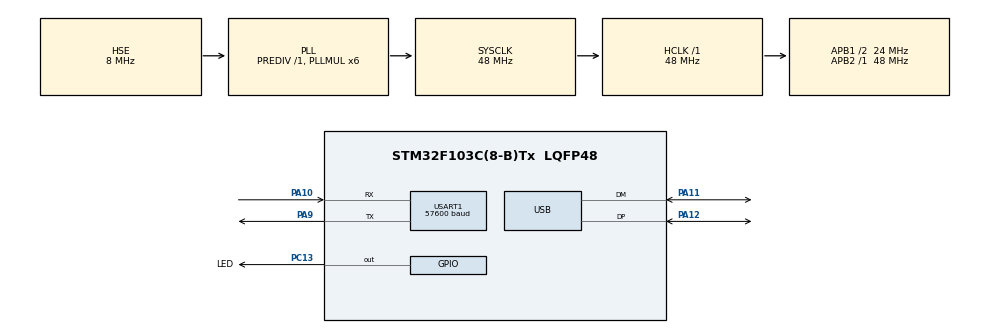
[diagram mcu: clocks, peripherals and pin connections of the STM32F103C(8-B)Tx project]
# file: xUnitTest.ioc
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Mcu.Family=STM32F1
Mcu.Name=STM32F103C(8-B)Tx
Mcu.Package=LQFP48
NVIC.PriorityGroup=NVIC_PRIORITYGROUP_4
NVIC.TIM1_UP_IRQn=true\:0\:0\:false\:false\:true
NVIC.TimeBase=TIM1_UP_IRQn
NVIC.TimeBaseIP=TIM1
PA10.Mode=Asynchronous
PA10.Signal=USART1_RX
PA11.Mode=Device
PA11.Signal=USB_DM
PA12.Mode=Device
PA12.Signal=USB_DP
PA13.Mode=JTAG_5_pins
PA13.Signal=SYS_JTMS-SWDIO
PA14.Mode=JTAG_5_pins
PA14.Signal=SYS_JTCK-SWCLK
PA15.Mode=JTAG_5_pins
PA15.Signal=SYS_JTDI
PA9.Mode=Asynchronous
PA9.Signal=USART1_TX
PB3.Mode=JTAG_5_pins
PB3.Signal=SYS_JTDO-TRACESWO
PB4.Mode=JTAG_5_pins
PB4.Signal=SYS_NJTRST
PC13-TAMPER-RTC.GPIO_Label=LED
PC13-TAMPER-RTC.GPIO_ModeDefaultOutputPP=GPIO_MODE_OUTPUT_PP
PC13-TAMPER-RTC.GPIO_Speed=GPIO_SPEED_FREQ_HIGH
PC13-TAMPER-RTC.Signal=GPIO_Output
PC14-OSC32_IN.Mode=LSE-External-Oscillator
PC14-OSC32_IN.Signal=RCC_OSC32_IN
PC15-OSC32_OUT.Mode=LSE-External-Oscillator
PC15-OSC32_OUT.Signal=RCC_OSC32_OUT
PD0-OSC_IN.Mode=HSE-External-Oscillator
PD0-OSC_IN.Signal=RCC_OSC_IN
PD1-OSC_OUT.Mode=HSE-External-Oscillator
PD1-OSC_OUT.Signal=RCC_OSC_OUT
ProjectManager.HeapSize=0x200
ProjectManager.StackSize=0x400
ProjectManager.TargetToolchain=SW4STM32
RCC.AHBFreq_Value=48000000
RCC.APB1CLKDivider=RCC_HCLK_DIV2
RCC.APB1Freq_Value=24000000
RCC.APB1TimFreq_Value=48000000
RCC.APB2Freq_Value=48000000
RCC.APB2TimFreq_Value=48000000
RCC.HCLKFreq_Value=48000000
RCC.HSIState=RCC_HSI_ON
RCC.PLLMUL=RCC_PLL_MUL6
RCC.SYSCLKFreq_VALUE=48000000
RCC.SYSCLKSource=RCC_SYSCLKSOURCE_PLLCLK
RCC.USBFreq_Value=48000000
USART1.BaudRate=57600
VP_SYS_VS_tim1.Mode=TIM1
board=UartTest

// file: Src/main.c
/**
  ******************************************************************************
  * File Name          : main.c
  * Description        : Main program body
  ******************************************************************************
  *
  * COPYRIGHT(c) 2017 STMicroelectronics
  *
  * Redistribution and use in source and binary forms, with or without modification,
  * are permitted provided that the following conditions are met:
  *   1. Redistributions of source code must retain the above copyright notice,
  *      this list of conditions and the following disclaimer.
  *   2. Redistributions in binary form must reproduce the above copyright notice,
  *      this list of conditions and the following disclaimer in the documentation
  *      and/or other materials provided with the distribution.
  *   3. Neither the name of STMicroelectronics nor the names of its contributors
  *      may be used to endorse or promote products derived from this software
  *      without specific prior written permission.
  *
  * THIS SOFTWARE IS PROVIDED BY THE COPYRIGHT HOLDERS AND CONTRIBUTORS "AS IS"
  * AND ANY EXPRESS OR IMPLIED WARRANTIES, INCLUDING, BUT NOT LIMITED TO, THE
  * IMPLIED WARRANTIES OF MERCHANTABILITY AND FITNESS FOR A PARTICULAR PURPOSE ARE
  * DISCLAIMED. IN NO EVENT SHALL THE COPYRIGHT HOLDER OR CONTRIBUTORS BE LIABLE
  * FOR ANY DIRECT, INDIRECT, INCIDENTAL, SPECIAL, EXEMPLARY, OR CONSEQUENTIAL
  * DAMAGES (INCLUDING, BUT NOT LIMITED TO, PROCUREMENT OF SUBSTITUTE GOODS OR
  * SERVICES; LOSS OF USE, DATA, OR PROFITS; OR BUSINESS INTERRUPTION) HOWEVER
  * CAUSED AND ON ANY THEORY OF LIABILITY, WHETHER IN CONTRACT, STRICT LIABILITY,
  * OR TORT (INCLUDING NEGLIGENCE OR OTHERWISE) ARISING IN ANY WAY OUT OF THE USE
  * OF THIS SOFTWARE, EVEN IF ADVISED OF THE POSSIBILITY OF SUCH DAMAGE.
  *
  ******************************************************************************
  */
#include "main.h"
#include "stm32f1xx_hal.h"

UART_HandleTypeDef huart1;

PCD_HandleTypeDef hpcd_USB_FS;

/* USER CODE BEGIN PV */
/* Private variables ---------------------------------------------------------*/

/* USER CODE END PV */

void SystemClock_Config(void);
void Error_Handler(void);
static void MX_GPIO_Init(void);
static void MX_USART1_UART_Init(void);
static void MX_USB_PCD_Init(void);

/* USER CODE BEGIN PFP */
/* Private function prototypes -----------------------------------------------*/

/* USER CODE END PFP */

int main(void)
{

  /* MCU Configuration----------------------------------------------------------*/

  /* Reset of all peripherals, Initializes the Flash interface and the Systick. */
  HAL_Init();

  /* Configure the system clock */
  SystemClock_Config();

  /* Initialize all configured peripherals */
  MX_GPIO_Init();
  MX_USART1_UART_Init();
  MX_USB_PCD_Init();

  /* Infinite loop */
  while (1)
  {

  /* USER CODE BEGIN 3 */
	HAL_GPIO_TogglePin(LED_GPIO_Port, LED_Pin); //Toggle the state of pin PC13
	HAL_Delay(500);
  }
  /* USER CODE END 3 */

}

/** System Clock Configuration
*/
void SystemClock_Config(void)
{

  RCC_OscInitTypeDef RCC_OscInitStruct;
  RCC_ClkInitTypeDef RCC_ClkInitStruct;
  RCC_PeriphCLKInitTypeDef PeriphClkInit;

    /**Initializes the CPU, AHB and APB busses clocks
    */
  RCC_OscInitStruct.OscillatorType = RCC_OSCILLATORTYPE_HSE;
  RCC_OscInitStruct.HSEState = RCC_HSE_ON;
  RCC_OscInitStruct.HSEPredivValue = RCC_HSE_PREDIV_DIV1;
  RCC_OscInitStruct.HSIState = RCC_HSI_ON;
  RCC_OscInitStruct.PLL.PLLState = RCC_PLL_ON;
  RCC_OscInitStruct.PLL.PLLSource = RCC_PLLSOURCE_HSE;
  RCC_OscInitStruct.PLL.PLLMUL = RCC_PLL_MUL6;
  if (HAL_RCC_OscConfig(&RCC_OscInitStruct) != HAL_OK)
  {
    Error_Handler();
  }

    /**Initializes the CPU, AHB and APB busses clocks
    */
  RCC_ClkInitStruct.ClockType = RCC_CLOCKTYPE_HCLK|RCC_CLOCKTYPE_SYSCLK
                              |RCC_CLOCKTYPE_PCLK1|RCC_CLOCKTYPE_PCLK2;
  RCC_ClkInitStruct.SYSCLKSource = RCC_SYSCLKSOURCE_PLLCLK;
  RCC_ClkInitStruct.AHBCLKDivider = RCC_SYSCLK_DIV1;
  RCC_ClkInitStruct.APB1CLKDivider = RCC_HCLK_DIV2;
  RCC_ClkInitStruct.APB2CLKDivider = RCC_HCLK_DIV1;

  if (HAL_RCC_ClockConfig(&RCC_ClkInitStruct, FLASH_LATENCY_1) != HAL_OK)
  {
    Error_Handler();
  }

  PeriphClkInit.PeriphClockSelection = RCC_PERIPHCLK_USB;
  PeriphClkInit.UsbClockSelection = RCC_USBCLKSOURCE_PLL;
  if (HAL_RCCEx_PeriphCLKConfig(&PeriphClkInit) != HAL_OK)
  {
    Error_Handler();
  }

    /**Configure the Systick interrupt time
    */
  HAL_SYSTICK_Config(HAL_RCC_GetHCLKFreq()/1000);

    /**Configure the Systick
    */
  HAL_SYSTICK_CLKSourceConfig(SYSTICK_CLKSOURCE_HCLK);

  /* SysTick_IRQn interrupt configuration */
  HAL_NVIC_SetPriority(SysTick_IRQn, 0, 0);
}

/* USART1 init function */
static void MX_USART1_UART_Init(void)
{

  huart1.Instance = USART1;
  huart1.Init.BaudRate = 57600;
  huart1.Init.WordLength = UART_WORDLENGTH_8B;
  huart1.Init.StopBits = UART_STOPBITS_1;
  huart1.Init.Parity = UART_PARITY_NONE;
  huart1.Init.Mode = UART_MODE_TX_RX;
  huart1.Init.HwFlowCtl = UART_HWCONTROL_NONE;
  huart1.Init.OverSampling = UART_OVERSAMPLING_16;
  if (HAL_UART_Init(&huart1) != HAL_OK)
  {
    Error_Handler();
  }

}

/* USB init function */
static void MX_USB_PCD_Init(void)
{

  hpcd_USB_FS.Instance = USB;
  hpcd_USB_FS.Init.dev_endpoints = 8;
  hpcd_USB_FS.Init.speed = PCD_SPEED_FULL;
  hpcd_USB_FS.Init.ep0_mps = DEP0CTL_MPS_8;
  hpcd_USB_FS.Init.low_power_enable = DISABLE;
  hpcd_USB_FS.Init.lpm_enable = DISABLE;
  hpcd_USB_FS.Init.battery_charging_enable = DISABLE;
  if (HAL_PCD_Init(&hpcd_USB_FS) != HAL_OK)
  {
    Error_Handler();
  }

}

/** Configure pins as
        * Analog
        * Input
        * Output
        * EVENT_OUT
        * EXTI
*/
static void MX_GPIO_Init(void)
{

  GPIO_InitTypeDef GPIO_InitStruct;

  /* GPIO Ports Clock Enable */
  __HAL_RCC_GPIOC_CLK_ENABLE();
  __HAL_RCC_GPIOD_CLK_ENABLE();
  __HAL_RCC_GPIOA_CLK_ENABLE();
  __HAL_RCC_GPIOB_CLK_ENABLE();

  /*Configure GPIO pin Output Level */
  HAL_GPIO_WritePin(LED_GPIO_Port, LED_Pin, GPIO_PIN_RESET);

  /*Configure GPIO pin : LED_Pin */
  GPIO_InitStruct.Pin = LED_Pin;
  GPIO_InitStruct.Mode = GPIO_MODE_OUTPUT_PP;
  GPIO_InitStruct.Speed = GPIO_SPEED_FREQ_HIGH;
  HAL_GPIO_Init(LED_GPIO_Port, &GPIO_InitStruct);

}

void Error_Handler(void)
{
  while(1)
  {
  }
}

/************************ (C) COPYRIGHT STMicroelectronics *****END OF FILE****/
